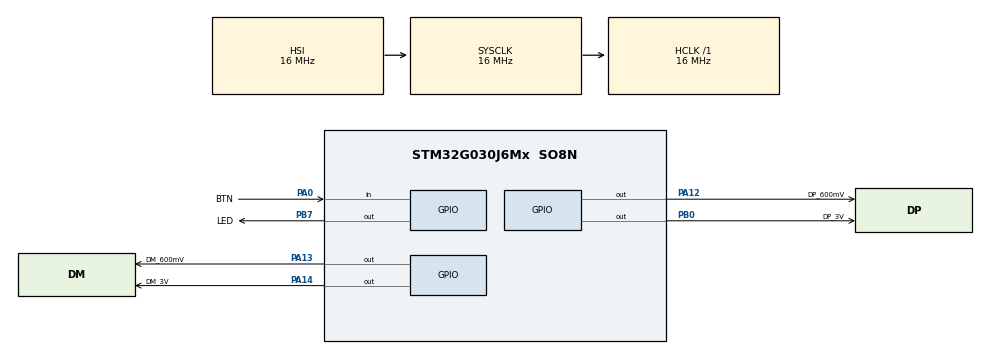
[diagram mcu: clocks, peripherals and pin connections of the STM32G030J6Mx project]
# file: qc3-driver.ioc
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Mcu.Family=STM32G0
Mcu.Name=STM32G030J6Mx
Mcu.Package=SO8N
PA0.GPIO_Label=BTN
PA0.GPIO_PuPd=GPIO_PULLUP
PA0.Signal=GPIO_Input
PA12\ [PA10].GPIO_Label=DP_600mV
PA12\ [PA10].Signal=GPIO_Output
PA13.GPIO_Label=DM_600mV
PA13.Signal=GPIO_Output
PA14-BOOT0.GPIO_Label=DM_3V
PA14-BOOT0.Signal=GPIO_Output
PB0.GPIO_Label=DP_3V
PB0.Signal=GPIO_Output
PB7.GPIO_Label=LED
PB7.Signal=GPIO_Output
ProjectManager.HeapSize=0x200
ProjectManager.StackSize=0x400
ProjectManager.TargetToolchain=STM32CubeIDE
RCC.AHBFreq_Value=16000000
RCC.CortexFreq_Value=16000000
RCC.EXTERNAL_CLOCK_VALUE=12288000
RCC.HCLKFreq_Value=16000000
RCC.HSE_VALUE=8000000
RCC.HSI_VALUE=16000000
RCC.LSE_VALUE=32768
RCC.SYSCLKFreq_VALUE=16000000
RCC.VCOOutputFreq_Value=128000000
board=custom

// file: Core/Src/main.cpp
/* USER CODE BEGIN Header */
/**
  ******************************************************************************
  * @file           : main.c
  * @brief          : Main program body
  ******************************************************************************
  * @attention
  *
  * <h2><center>&copy; Copyright (c) 2020 STMicroelectronics.
  * All rights reserved.</center></h2>
  *
  * This software component is licensed by ST under BSD 3-Clause license,
  * the "License"; You may not use this file except in compliance with the
  * License. You may obtain a copy of the License at:
  *                        opensource.org/licenses/BSD-3-Clause
  *
  ******************************************************************************
  */

/* USER CODE END Header */

#include "main.h"

/* USER CODE BEGIN Includes */

//////////////////////////////////////////////////////////////////////////////////////////

#include <DataSignal.h>
#include <Button.h>
#include <QC3Controller.h>
#include <Led.h>
#include <Driver.h>

//////////////////////////////////////////////////////////////////////////////////////////

/* USER CODE END Includes */

void SystemClock_Config(void);
static void MX_GPIO_Init(void);

int main(void)
{

  /* MCU Configuration--------------------------------------------------------*/

  /* Reset of all peripherals, Initializes the Flash interface and the Systick. */
  HAL_Init();

  /* Configure the system clock */
  SystemClock_Config();

  /* Initialize all configured peripherals */
  MX_GPIO_Init();
  /* USER CODE BEGIN 2 */

  //////////////////////////////////////////////////////////////////////////////////////////

  // Inicjalizacja sygnałów DATA+ i DATA-
  DataSignal dp(DP_3V_GPIO_Port, DP_3V_Pin, DP_600mV_GPIO_Port,  DP_600mV_Pin);
  DataSignal dm(DM_3V_GPIO_Port, DM_3V_Pin, DM_600mV_GPIO_Port, DM_600mV_Pin);

  // Inicjalizacja kontrolera QuickCharge3 i przekazanie instancji sygnałów
  QC3Controller qc3(&dp, &dm);

  // Inicjalizacja przycisku
  Button btn(BTN_GPIO_Port, BTN_Pin);

  // Inicjalizacja diody LED
  Led led(LED_GPIO_Port, LED_Pin);

  // Inicjalizacja sterownika (zebranie wszystkich obsługiwanych peryferiów)
  Driver driver(&qc3, &btn, &led);

  //////////////////////////////////////////////////////////////////////////////////////////

  /* USER CODE END 2 */

  /* Infinite loop */
  /* USER CODE BEGIN WHILE */
  while (1)
  {
	  ///////////////////////////////////////////////////////////////////////////////

	  // Wywołanie metody uruchamiającej program sterownika
	  driver.program();

	  //////////////////////////////////////////////////////////////////////////////

    /* USER CODE END WHILE */

  }
}

void SystemClock_Config(void)
{
  RCC_OscInitTypeDef RCC_OscInitStruct = {0};
  RCC_ClkInitTypeDef RCC_ClkInitStruct = {0};

  /** Configure the main internal regulator output voltage
  */
  HAL_PWREx_ControlVoltageScaling(PWR_REGULATOR_VOLTAGE_SCALE1);
  /** Initializes the RCC Oscillators according to the specified parameters
  * in the RCC_OscInitTypeDef structure.
  */
  RCC_OscInitStruct.OscillatorType = RCC_OSCILLATORTYPE_HSI;
  RCC_OscInitStruct.HSIState = RCC_HSI_ON;
  RCC_OscInitStruct.HSIDiv = RCC_HSI_DIV1;
  RCC_OscInitStruct.HSICalibrationValue = RCC_HSICALIBRATION_DEFAULT;
  RCC_OscInitStruct.PLL.PLLState = RCC_PLL_NONE;
  if (HAL_RCC_OscConfig(&RCC_OscInitStruct) != HAL_OK)
  {
    Error_Handler();
  }
  /** Initializes the CPU, AHB and APB buses clocks
  */
  RCC_ClkInitStruct.ClockType = RCC_CLOCKTYPE_HCLK|RCC_CLOCKTYPE_SYSCLK
                              |RCC_CLOCKTYPE_PCLK1;
  RCC_ClkInitStruct.SYSCLKSource = RCC_SYSCLKSOURCE_HSI;
  RCC_ClkInitStruct.AHBCLKDivider = RCC_SYSCLK_DIV1;
  RCC_ClkInitStruct.APB1CLKDivider = RCC_HCLK_DIV1;

  if (HAL_RCC_ClockConfig(&RCC_ClkInitStruct, FLASH_LATENCY_0) != HAL_OK)
  {
    Error_Handler();
  }
}

static void MX_GPIO_Init(void)
{
  GPIO_InitTypeDef GPIO_InitStruct = {0};

  /* GPIO Ports Clock Enable */
  __HAL_RCC_GPIOB_CLK_ENABLE();
  __HAL_RCC_GPIOA_CLK_ENABLE();

  /*Configure GPIO pin Output Level */
  HAL_GPIO_WritePin(GPIOB, LED_Pin|DP_3V_Pin, GPIO_PIN_RESET);

  /*Configure GPIO pin Output Level */
  HAL_GPIO_WritePin(GPIOA, DP_600mV_Pin|DM_600mV_Pin|DM_3V_Pin, GPIO_PIN_RESET);

  /*Configure GPIO pins : LED_Pin DP_3V_Pin */
  GPIO_InitStruct.Pin = LED_Pin|DP_3V_Pin;
  GPIO_InitStruct.Mode = GPIO_MODE_OUTPUT_PP;
  GPIO_InitStruct.Pull = GPIO_NOPULL;
  GPIO_InitStruct.Speed = GPIO_SPEED_FREQ_LOW;
  HAL_GPIO_Init(GPIOB, &GPIO_InitStruct);

  /*Configure GPIO pin : BTN_Pin */
  GPIO_InitStruct.Pin = BTN_Pin;
  GPIO_InitStruct.Mode = GPIO_MODE_INPUT;
  GPIO_InitStruct.Pull = GPIO_NOPULL;
  HAL_GPIO_Init(BTN_GPIO_Port, &GPIO_InitStruct);

  /*Configure GPIO pins : DP_600mV_Pin DM_600mV_Pin DM_3V_Pin */
  GPIO_InitStruct.Pin = DP_600mV_Pin|DM_600mV_Pin|DM_3V_Pin;
  GPIO_InitStruct.Mode = GPIO_MODE_OUTPUT_PP;
  GPIO_InitStruct.Pull = GPIO_NOPULL;
  GPIO_InitStruct.Speed = GPIO_SPEED_FREQ_LOW;
  HAL_GPIO_Init(GPIOA, &GPIO_InitStruct);

}

void Error_Handler(void)
{
}

/************************ (C) COPYRIGHT STMicroelectronics *****END OF FILE****/
